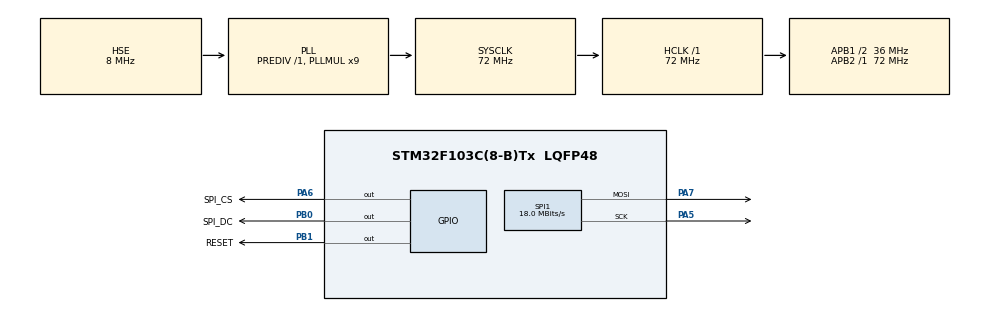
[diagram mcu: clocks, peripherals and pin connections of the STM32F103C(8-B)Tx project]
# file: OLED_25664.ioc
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Dma.Request0=SPI1_TX
Dma.SPI1_TX.0.Direction=DMA_MEMORY_TO_PERIPH
Dma.SPI1_TX.0.Instance=DMA1_Channel3
Dma.SPI1_TX.0.MemDataAlignment=DMA_MDATAALIGN_BYTE
Dma.SPI1_TX.0.MemInc=DMA_MINC_ENABLE
Dma.SPI1_TX.0.Mode=DMA_NORMAL
Dma.SPI1_TX.0.PeriphDataAlignment=DMA_PDATAALIGN_BYTE
Dma.SPI1_TX.0.PeriphInc=DMA_PINC_DISABLE
Dma.SPI1_TX.0.Priority=DMA_PRIORITY_LOW
Mcu.Family=STM32F1
Mcu.Name=STM32F103C(8-B)Tx
Mcu.Package=LQFP48
NVIC.DMA1_Channel3_IRQn=true\:0\:0\:false\:false\:true\:false\:true\:true
NVIC.PriorityGroup=NVIC_PRIORITYGROUP_4
NVIC.SPI1_IRQn=true\:0\:0\:false\:false\:true\:true\:true\:true
PA13.Mode=Serial_Wire
PA13.Signal=SYS_JTMS-SWDIO
PA14.Mode=Serial_Wire
PA14.Signal=SYS_JTCK-SWCLK
PA5.Mode=TX_Only_Simplex_Unidirect_Master
PA5.Signal=SPI1_SCK
PA6.GPIO_Label=SPI_CS
PA6.GPIO_Speed=GPIO_SPEED_FREQ_HIGH
PA6.PinState=GPIO_PIN_SET
PA6.Signal=GPIO_Output
PA7.Mode=TX_Only_Simplex_Unidirect_Master
PA7.Signal=SPI1_MOSI
PB0.GPIO_Label=SPI_DC
PB0.GPIO_Speed=GPIO_SPEED_FREQ_HIGH
PB0.PinState=GPIO_PIN_SET
PB0.Signal=GPIO_Output
PB1.GPIO_Label=RESET
PB1.GPIO_Speed=GPIO_SPEED_FREQ_HIGH
PB1.PinState=GPIO_PIN_SET
PB1.Signal=GPIO_Output
PD0-OSC_IN.Mode=HSE-External-Oscillator
PD0-OSC_IN.Signal=RCC_OSC_IN
PD1-OSC_OUT.Mode=HSE-External-Oscillator
PD1-OSC_OUT.Signal=RCC_OSC_OUT
ProjectManager.HeapSize=0x200
ProjectManager.StackSize=0x400
ProjectManager.TargetToolchain=STM32CubeIDE
RCC.AHBFreq_Value=72000000
RCC.APB1CLKDivider=RCC_HCLK_DIV2
RCC.APB1Freq_Value=36000000
RCC.APB1TimFreq_Value=72000000
RCC.APB2Freq_Value=72000000
RCC.APB2TimFreq_Value=72000000
RCC.HCLKFreq_Value=72000000
RCC.PLLMUL=RCC_PLL_MUL9
RCC.PLLSourceVirtual=RCC_PLLSOURCE_HSE
RCC.SYSCLKFreq_VALUE=72000000
RCC.SYSCLKSource=RCC_SYSCLKSOURCE_PLLCLK
RCC.USBFreq_Value=72000000
SPI1.BaudRatePrescaler=SPI_BAUDRATEPRESCALER_4
SPI1.CalculateBaudRate=18.0 MBits/s
SPI1.Direction=SPI_DIRECTION_2LINES
SPI1.Mode=SPI_MODE_MASTER
SPI1.VirtualType=VM_MASTER
board=custom

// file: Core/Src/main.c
/* USER CODE BEGIN Header */
/**
  ******************************************************************************
  * @file           : main.c
  * @brief          : Main program body
  ******************************************************************************
  * @attention
  *
  * Copyright (c) 2022 STMicroelectronics.
  * All rights reserved.
  *
  * This software is licensed under terms that can be found in the LICENSE file
  * in the root directory of this software component.
  * If no LICENSE file comes with this software, it is provided AS-IS.
  *
  ******************************************************************************
  */
/* USER CODE END Header */
#include "main.h"

/* USER CODE BEGIN Includes */
#include "drv_SSD1362.h"
#include "stdlib.h"
/* USER CODE END Includes */

SPI_HandleTypeDef hspi1;
DMA_HandleTypeDef hdma_spi1_tx;

void SystemClock_Config(void);
static void MX_GPIO_Init(void);
static void MX_DMA_Init(void);
static void MX_SPI1_Init(void);

int main(void)
{

  /* MCU Configuration--------------------------------------------------------*/

  /* Reset of all peripherals, Initializes the Flash interface and the Systick. */
  HAL_Init();

  /* Configure the system clock */
  SystemClock_Config();

  /* Initialize all configured peripherals */
  MX_GPIO_Init();
  MX_DMA_Init();
  MX_SPI1_Init();
  /* USER CODE BEGIN 2 */

  SSD1362_init();
  draw_fill_rect(0, 0, 255, 63, 0);
  update_gram();
  //Write_Rect(0, 0, 128, 64, 0x00);

  //Write_Rect(32, 16, 64, 32, 0x66);
  //Write_Rect(0, 0, 32, 16, 0xAA);
  /* USER CODE END 2 */

  /* Infinite loop */
  /* USER CODE BEGIN WHILE */
  while (1)
  {
	  for(uint8_t n = 0; n < 16; n++)
	  {

		  for(uint8_t i = 0; i < 16; i++)
		  {
			  draw_fill_rect(i * 16, 0, i * 16 + 15, 64, (i + n) & 0x0f);
		  }
		  //uint8_t delay = rand() & 0xff;
 		  update_gram();
		  HAL_Delay(20);
	  }
    /* USER CODE END WHILE */

  }
}

void SystemClock_Config(void)
{
  RCC_OscInitTypeDef RCC_OscInitStruct = {0};
  RCC_ClkInitTypeDef RCC_ClkInitStruct = {0};

  /** Initializes the RCC Oscillators according to the specified parameters
  * in the RCC_OscInitTypeDef structure.
  */
  RCC_OscInitStruct.OscillatorType = RCC_OSCILLATORTYPE_HSE;
  RCC_OscInitStruct.HSEState = RCC_HSE_ON;
  RCC_OscInitStruct.HSEPredivValue = RCC_HSE_PREDIV_DIV1;
  RCC_OscInitStruct.HSIState = RCC_HSI_ON;
  RCC_OscInitStruct.PLL.PLLState = RCC_PLL_ON;
  RCC_OscInitStruct.PLL.PLLSource = RCC_PLLSOURCE_HSE;
  RCC_OscInitStruct.PLL.PLLMUL = RCC_PLL_MUL9;
  if (HAL_RCC_OscConfig(&RCC_OscInitStruct) != HAL_OK)
  {
    Error_Handler();
  }

  /** Initializes the CPU, AHB and APB buses clocks
  */
  RCC_ClkInitStruct.ClockType = RCC_CLOCKTYPE_HCLK|RCC_CLOCKTYPE_SYSCLK
                              |RCC_CLOCKTYPE_PCLK1|RCC_CLOCKTYPE_PCLK2;
  RCC_ClkInitStruct.SYSCLKSource = RCC_SYSCLKSOURCE_PLLCLK;
  RCC_ClkInitStruct.AHBCLKDivider = RCC_SYSCLK_DIV1;
  RCC_ClkInitStruct.APB1CLKDivider = RCC_HCLK_DIV2;
  RCC_ClkInitStruct.APB2CLKDivider = RCC_HCLK_DIV1;

  if (HAL_RCC_ClockConfig(&RCC_ClkInitStruct, FLASH_LATENCY_2) != HAL_OK)
  {
    Error_Handler();
  }
}

static void MX_SPI1_Init(void)
{

  /* SPI1 parameter configuration*/
  hspi1.Instance = SPI1;
  hspi1.Init.Mode = SPI_MODE_MASTER;
  hspi1.Init.Direction = SPI_DIRECTION_2LINES;
  hspi1.Init.DataSize = SPI_DATASIZE_8BIT;
  hspi1.Init.CLKPolarity = SPI_POLARITY_LOW;
  hspi1.Init.CLKPhase = SPI_PHASE_1EDGE;
  hspi1.Init.NSS = SPI_NSS_SOFT;
  hspi1.Init.BaudRatePrescaler = SPI_BAUDRATEPRESCALER_4;
  hspi1.Init.FirstBit = SPI_FIRSTBIT_MSB;
  hspi1.Init.TIMode = SPI_TIMODE_DISABLE;
  hspi1.Init.CRCCalculation = SPI_CRCCALCULATION_DISABLE;
  hspi1.Init.CRCPolynomial = 10;
  if (HAL_SPI_Init(&hspi1) != HAL_OK)
  {
    Error_Handler();
  }

}

static void MX_DMA_Init(void)
{

  /* DMA controller clock enable */
  __HAL_RCC_DMA1_CLK_ENABLE();

  /* DMA interrupt init */
  /* DMA1_Channel3_IRQn interrupt configuration */
  HAL_NVIC_SetPriority(DMA1_Channel3_IRQn, 0, 0);
  HAL_NVIC_EnableIRQ(DMA1_Channel3_IRQn);

}

static void MX_GPIO_Init(void)
{
  GPIO_InitTypeDef GPIO_InitStruct = {0};

  /* GPIO Ports Clock Enable */
  __HAL_RCC_GPIOD_CLK_ENABLE();
  __HAL_RCC_GPIOA_CLK_ENABLE();
  __HAL_RCC_GPIOB_CLK_ENABLE();

  /*Configure GPIO pin Output Level */
  HAL_GPIO_WritePin(SPI_CS_GPIO_Port, SPI_CS_Pin, GPIO_PIN_SET);

  /*Configure GPIO pin Output Level */
  HAL_GPIO_WritePin(GPIOB, SPI_DC_Pin|RESET_Pin, GPIO_PIN_SET);

  /*Configure GPIO pin : SPI_CS_Pin */
  GPIO_InitStruct.Pin = SPI_CS_Pin;
  GPIO_InitStruct.Mode = GPIO_MODE_OUTPUT_PP;
  GPIO_InitStruct.Pull = GPIO_NOPULL;
  GPIO_InitStruct.Speed = GPIO_SPEED_FREQ_HIGH;
  HAL_GPIO_Init(SPI_CS_GPIO_Port, &GPIO_InitStruct);

  /*Configure GPIO pins : SPI_DC_Pin RESET_Pin */
  GPIO_InitStruct.Pin = SPI_DC_Pin|RESET_Pin;
  GPIO_InitStruct.Mode = GPIO_MODE_OUTPUT_PP;
  GPIO_InitStruct.Pull = GPIO_NOPULL;
  GPIO_InitStruct.Speed = GPIO_SPEED_FREQ_HIGH;
  HAL_GPIO_Init(GPIOB, &GPIO_InitStruct);

}

void Error_Handler(void)
{
  __disable_irq();
  while (1)
  {
  }
}
